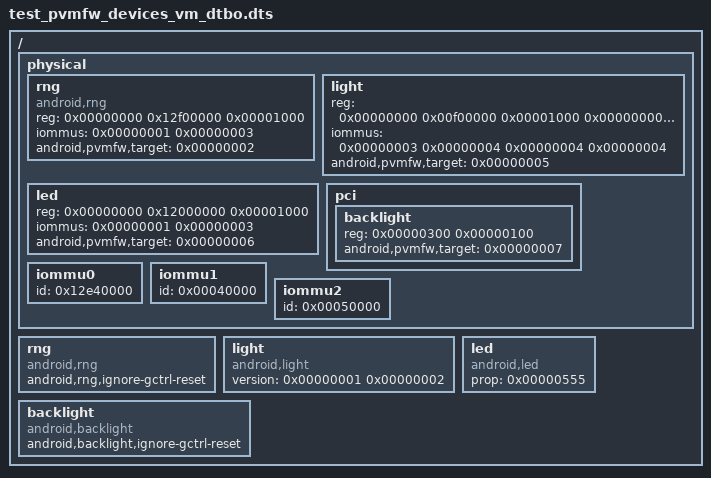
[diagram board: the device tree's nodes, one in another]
/dts-v1/;
/plugin/;

/ {
    physical {
        #address-cells = <0x00000002>;
        #size-cells = <0x00000001>;
        rng {
            compatible = "android,rng";
            reg = <0x00000000 0x12f00000 0x00001000>;
            iommus = <0x00000001 0x00000003>;
            android,pvmfw,target = <0x00000002>;
        };
        light {
            reg = <0x00000000 0x00f00000 0x00001000 0x00000000 0x00f10000 0x00001000>;
            iommus = <0x00000003 0x00000004 0x00000004 0x00000004>;
            android,pvmfw,target = <0x00000005>;
        };
        led {
            reg = <0x00000000 0x12000000 0x00001000>;
            iommus = <0x00000001 0x00000003>;
            android,pvmfw,target = <0x00000006>;
        };
        pci {
            #address-cells = <0x00000001>;
            #size-cells = <0x00000001>;
            backlight {
                reg = <0x00000300 0x00000100>;
                android,pvmfw,target = <0x00000007>;
            };
        };
        iommu0 {
            #iommu-cells = <0x00000001>;
            id = <0x12e40000>;
            phandle = <0x00000001>;
        };
        iommu1 {
            #iommu-cells = <0x00000001>;
            id = <0x00040000>;
            phandle = <0x00000003>;
        };
        iommu2 {
            #iommu-cells = <0x00000001>;
            id = <0x00050000>;
            phandle = <0x00000004>;
        };
    };
    fragment@rng {
        target-path = "/";
        __overlay__ {
            rng {
                compatible = "android,rng";
                android,rng,ignore-gctrl-reset;
                phandle = <0x00000002>;
            };
        };
    };
    fragment@sensor {
        target-path = "/";
        __overlay__ {
            light {
                compatible = "android,light";
                version = <0x00000001 0x00000002>;
                phandle = <0x00000005>;
            };
        };
    };
    fragment@led {
        target-path = "/";
        __overlay__ {
            led {
                compatible = "android,led";
                prop = <0x00000555>;
                phandle = <0x00000006>;
            };
        };
    };
    fragment@backlight {
        target-path = "/";
        __overlay__ {
            backlight {
                compatible = "android,backlight";
                android,backlight,ignore-gctrl-reset;
                phandle = <0x00000007>;
            };
        };
    };
    __symbols__ {
        iommu0 = "/physical/iommu0";
        iommu1 = "/physical/iommu1";
        iommu2 = "/physical/iommu2";
        rng = "/fragment@rng/__overlay__/rng";
        light = "/fragment@sensor/__overlay__/light";
        led = "/fragment@led/__overlay__/led";
        backlight = "/fragment@backlight/__overlay__/backlight";
    };
    __local_fixups__ {
        physical {
            rng {
                iommus = <0x00000000>;
                android,pvmfw,target = <0x00000000>;
            };
            light {
                iommus = <0x00000000 0x00000008>;
                android,pvmfw,target = <0x00000000>;
            };
            led {
                iommus = <0x00000000>;
                android,pvmfw,target = <0x00000000>;
            };
            pci {
                backlight {
                    android,pvmfw,target = <0x00000000>;
                };
            };
        };
    };
};
